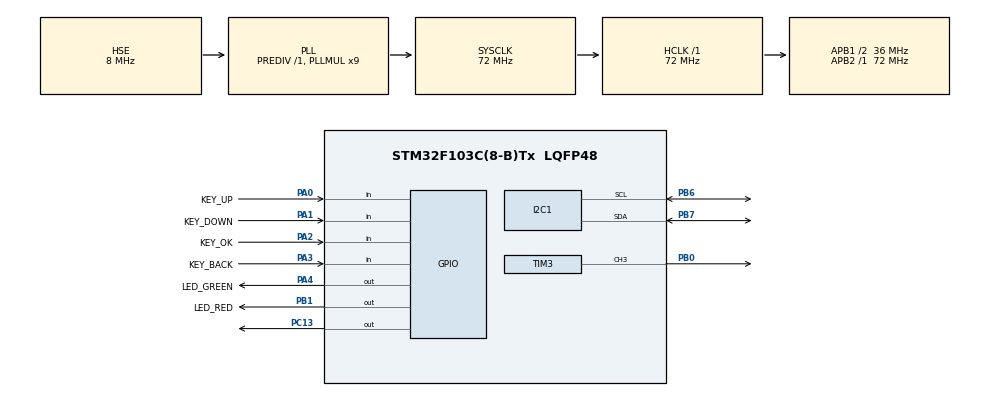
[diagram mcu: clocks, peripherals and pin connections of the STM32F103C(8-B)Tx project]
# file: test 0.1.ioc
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Mcu.Family=STM32F1
Mcu.Name=STM32F103C(8-B)Tx
Mcu.Package=LQFP48
NVIC.PriorityGroup=NVIC_PRIORITYGROUP_4
PA0-WKUP.GPIO_Label=KEY_UP
PA0-WKUP.GPIO_PuPd=GPIO_PULLUP
PA0-WKUP.Signal=GPIO_Input
PA1.GPIO_Label=KEY_DOWN
PA1.GPIO_PuPd=GPIO_PULLUP
PA1.Signal=GPIO_Input
PA13.Mode=Serial_Wire
PA13.Signal=SYS_JTMS-SWDIO
PA14.Mode=Serial_Wire
PA14.Signal=SYS_JTCK-SWCLK
PA2.GPIO_Label=KEY_OK
PA2.GPIO_PuPd=GPIO_PULLUP
PA2.Signal=GPIO_Input
PA3.GPIO_Label=KEY_BACK
PA3.GPIO_PuPd=GPIO_PULLUP
PA3.Signal=GPIO_Input
PA4.GPIO_Label=LED_GREEN
PA4.GPIO_ModeDefaultOutputPP=GPIO_MODE_OUTPUT_OD
PA4.GPIO_PuPd=GPIO_NOPULL
PA4.PinState=GPIO_PIN_SET
PA4.Signal=GPIO_Output
PB0.Signal=S_TIM3_CH3
PB1.GPIO_Label=LED_RED
PB1.GPIO_ModeDefaultOutputPP=GPIO_MODE_OUTPUT_OD
PB1.GPIO_PuPd=GPIO_NOPULL
PB1.PinState=GPIO_PIN_SET
PB1.Signal=GPIO_Output
PB6.Mode=I2C
PB6.Signal=I2C1_SCL
PB7.Mode=I2C
PB7.Signal=I2C1_SDA
PC13-TAMPER-RTC.GPIO_ModeDefaultOutputPP=GPIO_MODE_OUTPUT_OD
PC13-TAMPER-RTC.GPIO_PuPd=GPIO_PULLUP
PC13-TAMPER-RTC.PinState=GPIO_PIN_SET
PC13-TAMPER-RTC.Signal=GPIO_Output
PD0-OSC_IN.Mode=HSE-External-Oscillator
PD0-OSC_IN.Signal=RCC_OSC_IN
PD1-OSC_OUT.Mode=HSE-External-Oscillator
PD1-OSC_OUT.Signal=RCC_OSC_OUT
ProjectManager.HeapSize=0x200
ProjectManager.StackSize=0x400
ProjectManager.TargetToolchain=MDK-ARM V5.32
RCC.AHBFreq_Value=72000000
RCC.APB1CLKDivider=RCC_HCLK_DIV2
RCC.APB1Freq_Value=36000000
RCC.APB1TimFreq_Value=72000000
RCC.APB2Freq_Value=72000000
RCC.APB2TimFreq_Value=72000000
RCC.HCLKFreq_Value=72000000
RCC.PLLMUL=RCC_PLL_MUL9
RCC.PLLSourceVirtual=RCC_PLLSOURCE_HSE
RCC.SYSCLKFreq_VALUE=72000000
RCC.SYSCLKSource=RCC_SYSCLKSOURCE_PLLCLK
RCC.USBFreq_Value=72000000
SH.S_TIM3_CH3.0=TIM3_CH3,PWM Generation3 CH3
TIM3.AutoReloadPreload=TIM_AUTORELOAD_PRELOAD_ENABLE
TIM3.Channel-PWM\ Generation3\ CH3=TIM_CHANNEL_3
TIM3.OCPolarity_3=TIM_OCPOLARITY_LOW
TIM3.Period=369
TIM3.Prescaler=71
TIM3.Pulse-PWM\ Generation3\ CH3=185
VP_TIM3_VS_ClockSourceINT.Mode=Internal
board=custom

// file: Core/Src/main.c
/* USER CODE BEGIN Header */
/**
  ******************************************************************************
  * @file           : main.c
  * @brief          : Main program body
  ******************************************************************************
  * @attention
  *
  * Copyright (c) 2026 STMicroelectronics.
  * All rights reserved.
  *
  * This software is licensed under terms that can be found in the LICENSE file
  * in the root directory of this software component.
  * If no LICENSE file comes with this software, it is provided AS-IS.
  *
  ******************************************************************************
  */
/* USER CODE END Header */
#include "main.h"

/* USER CODE BEGIN Includes */
#include"key.h"
#include"ui.h"
/* USER CODE END Includes */

I2C_HandleTypeDef hi2c1;

TIM_HandleTypeDef htim3;

void SystemClock_Config(void);
static void MX_GPIO_Init(void);
static void MX_I2C1_Init(void);
static void MX_TIM3_Init(void);

/* USER CODE BEGIN 0 */

/* ==================== 项目总览（读代码从这里开始） ====================
 * 作品：STM32F103C8T6 菜单式电子密码锁
 * 硬件：OLED(I2C1: PB6/PB7)；4 按键(PA0~PA3)；蜂鸣器(PB0=TIM3_CH3)；
 *       绿灯(PA4)/红灯(PB1)；SWD 下载口(PA13/PA14)
 * 软件分层（上层调用下层，别跨级乱调）：
 *   驱动层：key.c 按键 | oled.c 屏幕 | buzzer.c 蜂鸣器 | led.c 状态灯
 *   服务层：clock.c 时钟 | settings.c 密码/输错次数存取
 *   应用层：ui.c 页面状态机（主循环只调 ui_task()）
 * 主循环：while(1) { ui_task(); }；按键扫描、蜂鸣器播放在 SysTick 中断里跑。
 * 逐步解读：见项目 docs\代码导读手册.md（按顺序读）
 * ==================================================================== */

/* USER CODE END 0 */

int main(void)
{

  /* MCU Configuration--------------------------------------------------------*/

  /* Reset of all peripherals, Initializes the Flash interface and the Systick. */
  HAL_Init();

  /* Configure the system clock */
  SystemClock_Config();

  /* Initialize all configured peripherals */
  MX_GPIO_Init();
  MX_I2C1_Init();
  MX_TIM3_Init();
  /* USER CODE BEGIN 2 */
  key_init();	// 初始化按键（引脚已由 CubeMX 配好）
  ui_init();	// 初始化 OLED 屏幕、时钟和界面
  /* USER CODE END 2 */

  /* Infinite loop */
  while (1)
  {

    /* USER CODE BEGIN 3 */
    ui_task();	// 界面任务：走时 + 刷新屏幕
  }
  /* USER CODE END 3 */
}

void SystemClock_Config(void)
{
  RCC_OscInitTypeDef RCC_OscInitStruct = {0};
  RCC_ClkInitTypeDef RCC_ClkInitStruct = {0};

  /** Initializes the RCC Oscillators according to the specified parameters
  * in the RCC_OscInitTypeDef structure.
  */
  RCC_OscInitStruct.OscillatorType = RCC_OSCILLATORTYPE_HSE;
  RCC_OscInitStruct.HSEState = RCC_HSE_ON;
  RCC_OscInitStruct.HSEPredivValue = RCC_HSE_PREDIV_DIV1;
  RCC_OscInitStruct.HSIState = RCC_HSI_ON;
  RCC_OscInitStruct.PLL.PLLState = RCC_PLL_ON;
  RCC_OscInitStruct.PLL.PLLSource = RCC_PLLSOURCE_HSE;
  RCC_OscInitStruct.PLL.PLLMUL = RCC_PLL_MUL9;
  if (HAL_RCC_OscConfig(&RCC_OscInitStruct) != HAL_OK)
  {
    Error_Handler();
  }

  /** Initializes the CPU, AHB and APB buses clocks
  */
  RCC_ClkInitStruct.ClockType = RCC_CLOCKTYPE_HCLK|RCC_CLOCKTYPE_SYSCLK
                              |RCC_CLOCKTYPE_PCLK1|RCC_CLOCKTYPE_PCLK2;
  RCC_ClkInitStruct.SYSCLKSource = RCC_SYSCLKSOURCE_PLLCLK;
  RCC_ClkInitStruct.AHBCLKDivider = RCC_SYSCLK_DIV1;
  RCC_ClkInitStruct.APB1CLKDivider = RCC_HCLK_DIV2;
  RCC_ClkInitStruct.APB2CLKDivider = RCC_HCLK_DIV1;

  if (HAL_RCC_ClockConfig(&RCC_ClkInitStruct, FLASH_LATENCY_2) != HAL_OK)
  {
    Error_Handler();
  }
}

static void MX_I2C1_Init(void)
{

  hi2c1.Instance = I2C1;
  hi2c1.Init.ClockSpeed = 100000;
  hi2c1.Init.DutyCycle = I2C_DUTYCYCLE_2;
  hi2c1.Init.OwnAddress1 = 0;
  hi2c1.Init.AddressingMode = I2C_ADDRESSINGMODE_7BIT;
  hi2c1.Init.DualAddressMode = I2C_DUALADDRESS_DISABLE;
  hi2c1.Init.OwnAddress2 = 0;
  hi2c1.Init.GeneralCallMode = I2C_GENERALCALL_DISABLE;
  hi2c1.Init.NoStretchMode = I2C_NOSTRETCH_DISABLE;
  if (HAL_I2C_Init(&hi2c1) != HAL_OK)
  {
    Error_Handler();
  }

}

static void MX_TIM3_Init(void)
{

  TIM_ClockConfigTypeDef sClockSourceConfig = {0};
  TIM_MasterConfigTypeDef sMasterConfig = {0};
  TIM_OC_InitTypeDef sConfigOC = {0};

  htim3.Instance = TIM3;
  htim3.Init.Prescaler = 71;
  htim3.Init.CounterMode = TIM_COUNTERMODE_UP;
  htim3.Init.Period = 369;
  htim3.Init.ClockDivision = TIM_CLOCKDIVISION_DIV1;
  htim3.Init.AutoReloadPreload = TIM_AUTORELOAD_PRELOAD_ENABLE;
  if (HAL_TIM_Base_Init(&htim3) != HAL_OK)
  {
    Error_Handler();
  }
  sClockSourceConfig.ClockSource = TIM_CLOCKSOURCE_INTERNAL;
  if (HAL_TIM_ConfigClockSource(&htim3, &sClockSourceConfig) != HAL_OK)
  {
    Error_Handler();
  }
  if (HAL_TIM_PWM_Init(&htim3) != HAL_OK)
  {
    Error_Handler();
  }
  sMasterConfig.MasterOutputTrigger = TIM_TRGO_RESET;
  sMasterConfig.MasterSlaveMode = TIM_MASTERSLAVEMODE_DISABLE;
  if (HAL_TIMEx_MasterConfigSynchronization(&htim3, &sMasterConfig) != HAL_OK)
  {
    Error_Handler();
  }
  sConfigOC.OCMode = TIM_OCMODE_PWM1;
  sConfigOC.Pulse = 185;
  sConfigOC.OCPolarity = TIM_OCPOLARITY_LOW;
  sConfigOC.OCFastMode = TIM_OCFAST_DISABLE;
  if (HAL_TIM_PWM_ConfigChannel(&htim3, &sConfigOC, TIM_CHANNEL_3) != HAL_OK)
  {
    Error_Handler();
  }
  HAL_TIM_MspPostInit(&htim3);

}

static void MX_GPIO_Init(void)
{
  GPIO_InitTypeDef GPIO_InitStruct = {0};

  /* GPIO Ports Clock Enable */
  __HAL_RCC_GPIOC_CLK_ENABLE();
  __HAL_RCC_GPIOD_CLK_ENABLE();
  __HAL_RCC_GPIOA_CLK_ENABLE();
  __HAL_RCC_GPIOB_CLK_ENABLE();

  /*Configure GPIO pin Output Level */
  HAL_GPIO_WritePin(GPIOC, GPIO_PIN_13, GPIO_PIN_SET);

  /*Configure GPIO pin Output Level */
  HAL_GPIO_WritePin(LED_GREEN_GPIO_Port, LED_GREEN_Pin, GPIO_PIN_SET);

  /*Configure GPIO pin Output Level */
  HAL_GPIO_WritePin(LED_RED_GPIO_Port, LED_RED_Pin, GPIO_PIN_SET);

  /*Configure GPIO pin : PC13 */
  GPIO_InitStruct.Pin = GPIO_PIN_13;
  GPIO_InitStruct.Mode = GPIO_MODE_OUTPUT_OD;
  GPIO_InitStruct.Pull = GPIO_PULLUP;
  GPIO_InitStruct.Speed = GPIO_SPEED_FREQ_LOW;
  HAL_GPIO_Init(GPIOC, &GPIO_InitStruct);

  /*Configure GPIO pins : KEY_UP_Pin KEY_DOWN_Pin KEY_OK_Pin KEY_BACK_Pin */
  GPIO_InitStruct.Pin = KEY_UP_Pin|KEY_DOWN_Pin|KEY_OK_Pin|KEY_BACK_Pin;
  GPIO_InitStruct.Mode = GPIO_MODE_INPUT;
  GPIO_InitStruct.Pull = GPIO_PULLUP;
  HAL_GPIO_Init(GPIOA, &GPIO_InitStruct);

  /*Configure GPIO pin : LED_GREEN_Pin */
  GPIO_InitStruct.Pin = LED_GREEN_Pin;
  GPIO_InitStruct.Mode = GPIO_MODE_OUTPUT_OD;
  GPIO_InitStruct.Pull = GPIO_NOPULL;
  GPIO_InitStruct.Speed = GPIO_SPEED_FREQ_LOW;
  HAL_GPIO_Init(LED_GREEN_GPIO_Port, &GPIO_InitStruct);

  /*Configure GPIO pin : LED_RED_Pin */
  GPIO_InitStruct.Pin = LED_RED_Pin;
  GPIO_InitStruct.Mode = GPIO_MODE_OUTPUT_OD;
  GPIO_InitStruct.Pull = GPIO_NOPULL;
  GPIO_InitStruct.Speed = GPIO_SPEED_FREQ_LOW;
  HAL_GPIO_Init(LED_RED_GPIO_Port, &GPIO_InitStruct);

}

void Error_Handler(void)
{
  __disable_irq();
  while (1)
  {
  }
}
